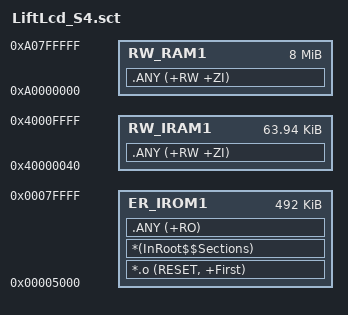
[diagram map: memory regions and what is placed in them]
; *************************************************************
; *** Scatter-Loading Description File generated by uVision ***
; *************************************************************

LR_IROM1 0x00005000 0x0007B000  {    ; load region size_region
  ER_IROM1 0x00005000 0x0007B000  {  ; load address = execution address
   *.o (RESET, +First)
   *(InRoot$$Sections)
   .ANY (+RO)
  }
  RW_RAM1 0xA0000000 0x00800000  {  ; RW data
   .ANY (+RW +ZI)
  }
  RW_IRAM1 0x40000040 0x0000FFC0  {
   .ANY (+RW +ZI)
  }
}

